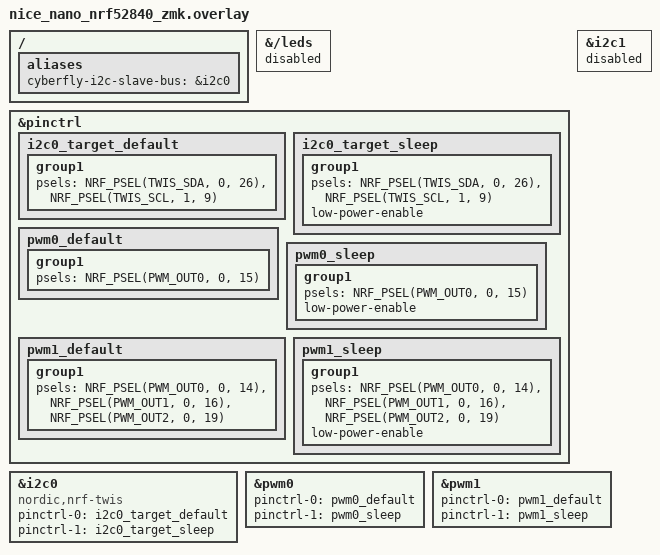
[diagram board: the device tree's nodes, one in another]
/*
 * Board-specific overlay for CyberFly Keyboard on nice!nano (nRF52840)
 * PWM0: backlight on P0.15
 * PWM1: RGB status LED on P0.14 (R), P0.16 (G), P0.19 (B)
 * I2C0 (TWIS): CyberFly I2C slave target on Qwiic (SDA=P0.26, SCL=P1.09)
 * The Qwiic pins are shared with QMI8658A, so this Meshtastic/CardKB
 * firmware mode disables the IMU/air-mouse bus.
 */

/* Disable the nice_nano on-board LED node to avoid conflict with P0.15 */
&{/leds} {
    status = "disabled";
};

/* I2C0 as TWIS (slave) on the physical Qwiic connector. */
&pinctrl {
    i2c0_target_default: i2c0_target_default {
        group1 {
            psels = <NRF_PSEL(TWIS_SDA, 0, 26)>,
                    <NRF_PSEL(TWIS_SCL, 1, 9)>;
        };
    };
    i2c0_target_sleep: i2c0_target_sleep {
        group1 {
            psels = <NRF_PSEL(TWIS_SDA, 0, 26)>,
                    <NRF_PSEL(TWIS_SCL, 1, 9)>;
            low-power-enable;
        };
    };
};

/* Keep the spare, non-Qwiic I2C peripheral disabled in this mode. */
&i2c1 {
    status = "disabled";
};

/ {
    aliases {
        cyberfly-i2c-slave-bus = &i2c0;
    };
};

/* PWM0 for backlight */
&pinctrl {
    pwm0_default: pwm0_default {
        group1 {
            psels = <NRF_PSEL(PWM_OUT0, 0, 15)>;
        };
    };
    pwm0_sleep: pwm0_sleep {
        group1 {
            psels = <NRF_PSEL(PWM_OUT0, 0, 15)>;
            low-power-enable;
        };
    };

    /* PWM1 for RGB LED */
    pwm1_default: pwm1_default {
        group1 {
            psels = <NRF_PSEL(PWM_OUT0, 0, 14)>,
                    <NRF_PSEL(PWM_OUT1, 0, 16)>,
                    <NRF_PSEL(PWM_OUT2, 0, 19)>;
        };
    };
    pwm1_sleep: pwm1_sleep {
        group1 {
            psels = <NRF_PSEL(PWM_OUT0, 0, 14)>,
                    <NRF_PSEL(PWM_OUT1, 0, 16)>,
                    <NRF_PSEL(PWM_OUT2, 0, 19)>;
            low-power-enable;
        };
    };
};

&i2c0 {
    compatible = "nordic,nrf-twis";
    status = "okay";
    pinctrl-0 = <&i2c0_target_default>;
    pinctrl-1 = <&i2c0_target_sleep>;
    pinctrl-names = "default", "sleep";
};

&pwm0 {
    status = "okay";
    pinctrl-0 = <&pwm0_default>;
    pinctrl-1 = <&pwm0_sleep>;
    pinctrl-names = "default", "sleep";
};

&pwm1 {
    status = "okay";
    pinctrl-0 = <&pwm1_default>;
    pinctrl-1 = <&pwm1_sleep>;
    pinctrl-names = "default", "sleep";
};
